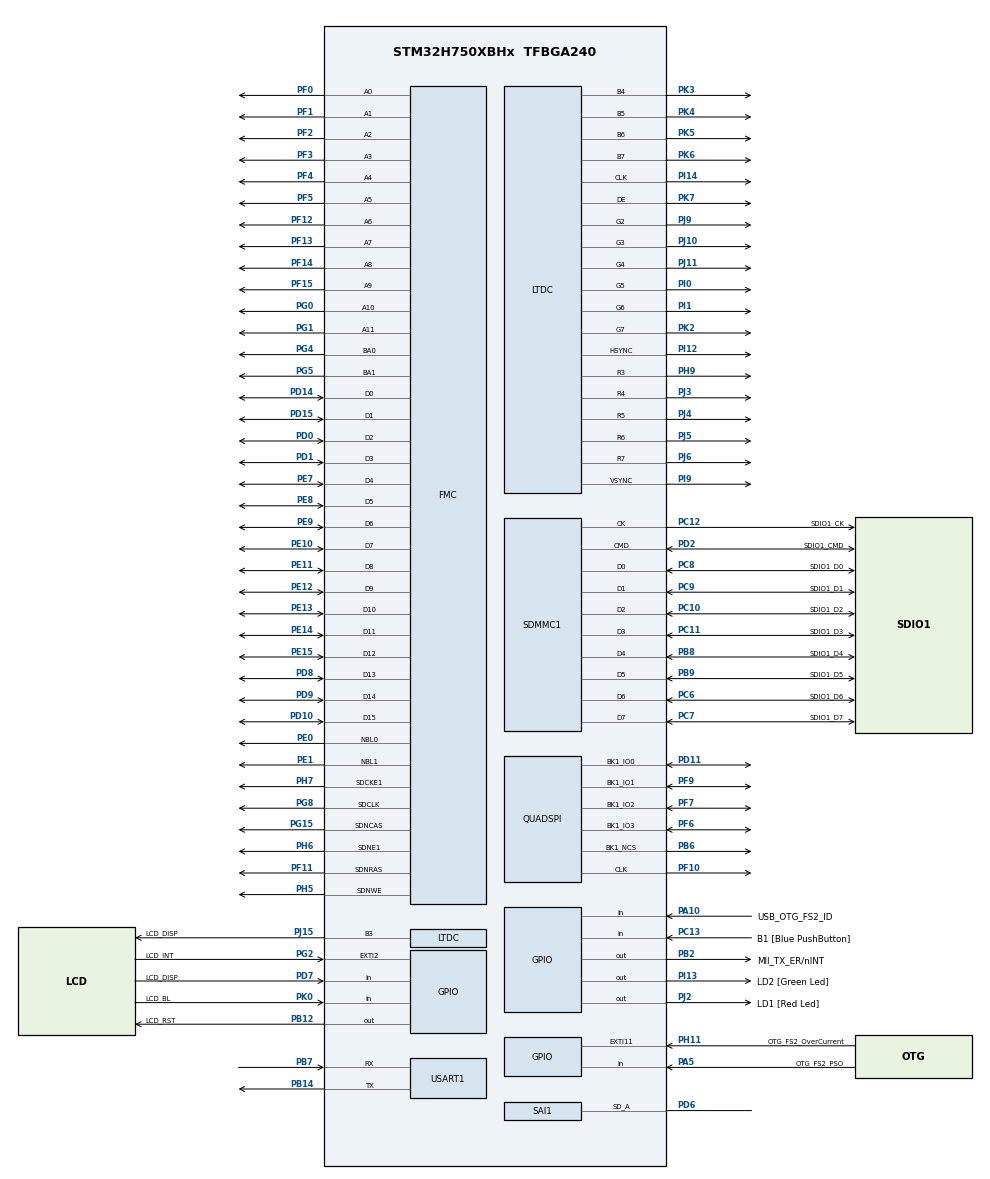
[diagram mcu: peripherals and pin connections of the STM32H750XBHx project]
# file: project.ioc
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FMC.CASLatency1=FMC_SDRAM_CAS_LATENCY_3
FMC.ExitSelfRefreshDelay1=7
FMC.LoadToActiveDelay1=2
FMC.RCDDelay1=2
FMC.RPDelay1=2
FMC.RPDelay2=2
FMC.ReadBurst1=FMC_SDRAM_RBURST_ENABLE
FMC.ReadBurst2=FMC_SDRAM_RBURST_ENABLE
FMC.RowCycleDelay1=7
FMC.RowCycleDelay2=7
FMC.SDClockPeriod1=FMC_SDRAM_CLOCK_PERIOD_2
FMC.SDClockPeriod2=FMC_SDRAM_CLOCK_PERIOD_2
FMC.SelfRefreshTime1=4
FMC.WriteRecoveryTime1=5
FREERTOS.Queues01=controlQueue,16,uint16_t,0,Dynamic,NULL,NULL
FREERTOS.Tasks01=defaultTask,24,128,StartDefaultTask,Default,NULL,Dynamic,NULL,NULL;TouchGFXTask,24,4096,TouchGFX_Task,As external,NULL,Dynamic,NULL,NULL;micListenTask,24,128,micListenTask_handler,Default,NULL,Dynamic,NULL,NULL;consumerTask,24,128,consumerTask_handler,Default,NULL,Dynamic,NULL,NULL;providerTask,24,128,providerTask_handler,Default,NULL,Dynamic,NULL,NULL
FREERTOS.configTOTAL_HEAP_SIZE=75000
FREERTOS.configUSE_NEWLIB_REENTRANT=1
LTDC.ActiveH=272
LTDC.ActiveW=480
LTDC.Alpha_L0=255
LTDC.FBStartAdress_L0=0x90000000
LTDC.ImageHeight_L0=272
LTDC.ImageWidth_L0=480
LTDC.Layers=0
LTDC.VSPolarity=LTDC_VSPOLARITY_AL
LTDC.WindowX1_L0=480
LTDC.WindowY1_L0=272
Mcu.Family=STM32H7
Mcu.Name=STM32H750XBHx
Mcu.Package=TFBGA240
Mdma.MDMA_Channel6.JPEG_OUTFIFO_TH.0.BlockCount=0
Mdma.MDMA_Channel6.JPEG_OUTFIFO_TH.0.BlockDataLength=0
Mdma.MDMA_Channel6.JPEG_OUTFIFO_TH.0.BufferTransferLength=32
Mdma.MDMA_Channel6.JPEG_OUTFIFO_TH.0.CircularMode=MDMA_LINEAR_LIST
Mdma.MDMA_Channel6.JPEG_OUTFIFO_TH.0.DataAlignment=MDMA_DATAALIGN_PACKENABLE
Mdma.MDMA_Channel6.JPEG_OUTFIFO_TH.0.DestBlockAddressOffset=0
Mdma.MDMA_Channel6.JPEG_OUTFIFO_TH.0.DestBurst=MDMA_DEST_BURST_32BEATS
Mdma.MDMA_Channel6.JPEG_OUTFIFO_TH.0.DestDataSize=MDMA_DEST_DATASIZE_BYTE
Mdma.MDMA_Channel6.JPEG_OUTFIFO_TH.0.DestinationInc=MDMA_DEST_INC_BYTE
Mdma.MDMA_Channel6.JPEG_OUTFIFO_TH.0.DstAddress=0
Mdma.MDMA_Channel6.JPEG_OUTFIFO_TH.0.Endianness=MDMA_LITTLE_ENDIANNESS_PRESERVE
Mdma.MDMA_Channel6.JPEG_OUTFIFO_TH.0.Instance=MDMA_Channel6
Mdma.MDMA_Channel6.JPEG_OUTFIFO_TH.0.MaskAddress=0
Mdma.MDMA_Channel6.JPEG_OUTFIFO_TH.0.MaskData=0
Mdma.MDMA_Channel6.JPEG_OUTFIFO_TH.0.Priority=MDMA_PRIORITY_LOW
Mdma.MDMA_Channel6.JPEG_OUTFIFO_TH.0.Rank=First
Mdma.MDMA_Channel6.JPEG_OUTFIFO_TH.0.SourceBlockAddressOffset=0
Mdma.MDMA_Channel6.JPEG_OUTFIFO_TH.0.SourceBurst=MDMA_SOURCE_BURST_SINGLE
Mdma.MDMA_Channel6.JPEG_OUTFIFO_TH.0.SourceDataSize=MDMA_SRC_DATASIZE_WORD
Mdma.MDMA_Channel6.JPEG_OUTFIFO_TH.0.SourceInc=MDMA_SRC_INC_DISABLE
Mdma.MDMA_Channel6.JPEG_OUTFIFO_TH.0.SrcAddress=0
Mdma.MDMA_Channel6.JPEG_OUTFIFO_TH.0.TransferTriggerMode=MDMA_BUFFER_TRANSFER
Mdma.MDMA_Channel6.Request0=JPEG_OUTFIFO_TH
Mdma.MDMA_Channel6.RequestsNb=1
Mdma.MDMA_Channel7.JPEG_INFIFO_TH.0.BlockCount=0
Mdma.MDMA_Channel7.JPEG_INFIFO_TH.0.BlockDataLength=0
Mdma.MDMA_Channel7.JPEG_INFIFO_TH.0.BufferTransferLength=32
Mdma.MDMA_Channel7.JPEG_INFIFO_TH.0.CircularMode=MDMA_LINEAR_LIST
Mdma.MDMA_Channel7.JPEG_INFIFO_TH.0.DataAlignment=MDMA_DATAALIGN_PACKENABLE
Mdma.MDMA_Channel7.JPEG_INFIFO_TH.0.DestBlockAddressOffset=0
Mdma.MDMA_Channel7.JPEG_INFIFO_TH.0.DestBurst=MDMA_DEST_BURST_32BEATS
Mdma.MDMA_Channel7.JPEG_INFIFO_TH.0.DestDataSize=MDMA_DEST_DATASIZE_WORD
Mdma.MDMA_Channel7.JPEG_INFIFO_TH.0.DestinationInc=MDMA_DEST_INC_DISABLE
Mdma.MDMA_Channel7.JPEG_INFIFO_TH.0.DstAddress=0
Mdma.MDMA_Channel7.JPEG_INFIFO_TH.0.Endianness=MDMA_LITTLE_ENDIANNESS_PRESERVE
Mdma.MDMA_Channel7.JPEG_INFIFO_TH.0.Instance=MDMA_Channel7
Mdma.MDMA_Channel7.JPEG_INFIFO_TH.0.MaskAddress=0
Mdma.MDMA_Channel7.JPEG_INFIFO_TH.0.MaskData=0
Mdma.MDMA_Channel7.JPEG_INFIFO_TH.0.Priority=MDMA_PRIORITY_LOW
Mdma.MDMA_Channel7.JPEG_INFIFO_TH.0.Rank=First
Mdma.MDMA_Channel7.JPEG_INFIFO_TH.0.SourceBlockAddressOffset=0
Mdma.MDMA_Channel7.JPEG_INFIFO_TH.0.SourceBurst=MDMA_SOURCE_BURST_32BEATS
Mdma.MDMA_Channel7.JPEG_INFIFO_TH.0.SourceDataSize=MDMA_SRC_DATASIZE_BYTE
Mdma.MDMA_Channel7.JPEG_INFIFO_TH.0.SourceInc=MDMA_SRC_INC_BYTE
Mdma.MDMA_Channel7.JPEG_INFIFO_TH.0.SrcAddress=0
Mdma.MDMA_Channel7.JPEG_INFIFO_TH.0.TransferTriggerMode=MDMA_BUFFER_TRANSFER
Mdma.MDMA_Channel7.Request0=JPEG_INFIFO_TH
Mdma.MDMA_Channel7.RequestsNb=1
Mdma.RequestSet0=MDMA_Channel7
Mdma.RequestSet1=MDMA_Channel6
Mdma.RequestSetsNb=2
NVIC.DMA2D_IRQn=true\:5\:0\:false\:false\:true\:true\:true\:true\:true
NVIC.LTDC_IRQn=true\:5\:0\:false\:false\:true\:true\:true\:true\:true
NVIC.MDMA_IRQn=true\:5\:0\:false\:false\:true\:true\:false\:true\:true
NVIC.PriorityGroup=NVIC_PRIORITYGROUP_4
NVIC.TIM6_DAC_IRQn=true\:15\:0\:false\:false\:true\:false\:false\:true\:true
NVIC.TimeBase=TIM6_DAC_IRQn
NVIC.TimeBaseIP=TIM6
NVIC.USART1_IRQn=true\:5\:0\:false\:false\:true\:true\:true\:true\:true
PA0_C.Signal=ADCx_INP0
PA1.GPIO_Label=MII_RX_CLK
PA1.Signal=ETH_RX_CLK
PA10.GPIO_Label=USB_OTG_FS2_ID
PA10.Signal=GPIO_Input
PA11.GPIO_Label=USB_OTG_FS2_N
PA11.Signal=USB_OTG_FS_DM
PA12.GPIO_Label=USB_OTG_FS2_P
PA12.Signal=USB_OTG_FS_DP
PA13\ (JTMS/SWDIO).Mode=JTAG_4_pins
PA13\ (JTMS/SWDIO).Signal=DEBUG_JTMS-SWDIO
PA14\ (JTCK/SWCLK).Mode=JTAG_4_pins
PA14\ (JTCK/SWCLK).Signal=DEBUG_JTCK-SWCLK
PA15\ (JTDI).Mode=JTAG_4_pins
PA15\ (JTDI).Signal=DEBUG_JTDI
PA1_C.Signal=ADCx_INP1
PA2.GPIO_Label=MII_MDIO
PA2.Signal=ETH_MDIO
PA5.GPIO_Label=OTG_FS2_PSO
PA5.Signal=GPIO_Input
PA6.Signal=S_TIM13_CH1
PA7.GPIO_Label=MII_RX_DV
PA7.Signal=ETH_RX_DV
PA8.Signal=S_TIM1_CH1
PA9.GPIO_Label=VBUS_FS2
PA9.Signal=USB_OTG_FS_VBUS
PB0.GPIO_Label=MII_RX_D2
PB0.Signal=ETH_RXD2
PB1.GPIO_Label=MII_RX_D3
PB1.Signal=ETH_RXD3
PB10.GPIO_Label=VCP_TX
PB10.Signal=USART3_TX
PB11.GPIO_Label=VCP_RX
PB11.Signal=USART3_RX
PB12.GPIO_Label=LCD_RST
PB12.Signal=GPIO_Output
PB13.GPIO_Label=FDCAN2_TX
PB13.Signal=FDCAN2_TX
PB14.Mode=Asynchronous
PB14.Signal=USART1_TX
PB15.Signal=SPI2_MOSI
PB2.GPIO_Label=MII_TX_ER/nINT
PB2.Signal=GPIO_Output
PB3\ (JTDO/TRACESWO).Mode=JTAG_4_pins
PB3\ (JTDO/TRACESWO).Signal=DEBUG_JTDO-SWO
PB4\ (NJTRST).Signal=SPI2_NSS
PB5.GPIO_Label=FDCAN2_RX
PB5.Signal=FDCAN2_RX
PB6.GPIO_Speed=GPIO_SPEED_FREQ_VERY_HIGH
PB6.Mode=Single Bank 1
PB6.Signal=QUADSPI_BK1_NCS
PB7.Mode=Asynchronous
PB7.Signal=USART1_RX
PB8.GPIO_Label=SDIO1_D4
PB8.Mode=mmc_8_bits_Wide_bus
PB8.Signal=SDMMC1_D4
PB9.GPIO_Label=SDIO1_D5
PB9.Mode=mmc_8_bits_Wide_bus
PB9.Signal=SDMMC1_D5
PC0.Signal=ADCx_INP10
PC1.GPIO_Label=MII_MDC
PC1.Signal=ETH_MDC
PC10.GPIO_Label=SDIO1_D2
PC10.Mode=mmc_8_bits_Wide_bus
PC10.Signal=SDMMC1_D2
PC11.GPIO_Label=SDIO1_D3
PC11.Mode=mmc_8_bits_Wide_bus
PC11.Signal=SDMMC1_D3
PC12.GPIO_Label=SDIO1_CK
PC12.Mode=mmc_8_bits_Wide_bus
PC12.Signal=SDMMC1_CK
PC13.GPIO_Label=B1 [Blue PushButton]
PC13.Signal=GPIO_Input
PC14-OSC32_IN\ (OSC32_IN).GPIO_Label=OSC32_IN
PC14-OSC32_IN\ (OSC32_IN).Mode=LSE-External-Clock-Source
PC14-OSC32_IN\ (OSC32_IN).Signal=RCC_OSC32_IN
PC15-OSC32_OUT\ (OSC32_OUT).GPIO_Label=OSC32_OUT
PC15-OSC32_OUT\ (OSC32_OUT).Signal=RCC_OSC32_OUT
PC2.GPIO_Label=MII_TXD2
PC2.Signal=ETH_TXD2
PC2_C.Signal=SharedAnalog_PC2
PC3.GPIO_Label=MII_TX_CLK
PC3.Signal=ETH_TX_CLK
PC3_C.Signal=ADC3_INP1
PC4.GPIO_Label=MII_RXD0
PC4.Signal=ETH_RXD0
PC5.GPIO_Label=MII_RXD1
PC5.Signal=ETH_RXD1
PC6.GPIO_Label=SDIO1_D6
PC6.Mode=mmc_8_bits_Wide_bus
PC6.Signal=SDMMC1_D6
PC7.GPIO_Label=SDIO1_D7
PC7.Mode=mmc_8_bits_Wide_bus
PC7.Signal=SDMMC1_D7
PC8.GPIO_Label=SDIO1_D0
PC8.Mode=mmc_8_bits_Wide_bus
PC8.Signal=SDMMC1_D0
PC9.GPIO_Label=SDIO1_D1
PC9.Mode=mmc_8_bits_Wide_bus
PC9.Signal=SDMMC1_D1
PD0.Signal=FMC_D2_DA2
PD1.Signal=FMC_D3_DA3
PD10.Signal=FMC_D15_DA15
PD11.GPIO_Speed=GPIO_SPEED_FREQ_VERY_HIGH
PD11.Mode=Single Bank 1
PD11.Signal=QUADSPI_BK1_IO0
PD14.Signal=FMC_D0_DA0
PD15.Signal=FMC_D1_DA1
PD2.GPIO_Label=SDIO1_CMD
PD2.Mode=mmc_8_bits_Wide_bus
PD2.Signal=SDMMC1_CMD
PD3.Signal=SPI2_SCK
PD6.Mode=SAI_A_SPDIF
PD6.Signal=SAI1_SD_A
PD7.GPIO_Label=LCD_DISP
PD7.Signal=GPIO_Input
PD8.Signal=FMC_D13_DA13
PD9.Signal=FMC_D14_DA14
PE0.Signal=FMC_NBL0
PE1.Signal=FMC_NBL1
PE10.Signal=FMC_D7_DA7
PE11.Signal=FMC_D8_DA8
PE12.Signal=FMC_D9_DA9
PE13.Signal=FMC_D10_DA10
PE14.Signal=FMC_D11_DA11
PE15.Signal=FMC_D12_DA12
PE2.GPIO_Label=MII_TXD3
PE2.Signal=ETH_TXD3
PE4.Signal=SAI4_D2
PE5.Signal=SAI4_CK2
PE7.Signal=FMC_D4_DA4
PE8.Signal=FMC_D5_DA5
PE9.Signal=FMC_D6_DA6
PF0.Signal=FMC_A0
PF1.Signal=FMC_A1
PF10.Mode=Single Bank 1
PF10.Signal=QUADSPI_CLK
PF11.Signal=FMC_SDNRAS
PF12.Signal=FMC_A6
PF13.Signal=FMC_A7
PF14.Signal=FMC_A8
PF15.Signal=FMC_A9
PF2.Signal=FMC_A2
PF3.Signal=FMC_A3
PF4.Signal=FMC_A4
PF5.Signal=FMC_A5
PF6.GPIO_Speed=GPIO_SPEED_FREQ_VERY_HIGH
PF6.Mode=Single Bank 1
PF6.Signal=QUADSPI_BK1_IO3
PF7.GPIO_Speed=GPIO_SPEED_FREQ_VERY_HIGH
PF7.Mode=Single Bank 1
PF7.Signal=QUADSPI_BK1_IO2
PF8.Signal=ADC3_INP7
PF9.GPIO_Speed=GPIO_SPEED_FREQ_VERY_HIGH
PF9.Mode=Single Bank 1
PF9.Signal=QUADSPI_BK1_IO1
PG0.Signal=FMC_A10
PG1.Signal=FMC_A11
PG10.Signal=SAI2_SD_B
PG11.GPIO_Label=MII_TX_EN
PG11.Signal=ETH_TX_EN
PG12.GPIO_Label=MII_TXD1
PG12.Signal=ETH_TXD1
PG13.GPIO_Label=MII_TXD0
PG13.Signal=ETH_TXD0
PG15.Signal=FMC_SDNCAS
PG2.GPIO_Label=LCD_INT
PG2.Signal=GPXTI2
PG4.Signal=FMC_A14_BA0
PG5.Signal=FMC_A15_BA1
PG7.GPIO_Label=audio_Int
PG7.Signal=SAI1_MCLK_A
PG8.Signal=FMC_SDCLK
PH0-OSC_IN\ (PH0).GPIO_Label=OSC_IN
PH0-OSC_IN\ (PH0).Mode=HSE-External-Clock-Source
PH0-OSC_IN\ (PH0).Signal=RCC_OSC_IN
PH1-OSC_OUT\ (PH1).GPIO_Label=OSC_OUT
PH1-OSC_OUT\ (PH1).Signal=RCC_OSC_OUT
PH11.GPIO_Label=OTG_FS2_OverCurrent
PH11.Signal=GPXTI11
PH13.GPIO_Label=FDCAN1_TX
PH13.Signal=FDCAN1_TX
PH14.GPIO_Label=FDCAN1_RX
PH14.Signal=FDCAN1_RX
PH15.Signal=TIM8_CH3N
PH2.GPIO_Label=MII_CRS
PH2.Signal=ETH_CRS
PH3.GPIO_Label=MII_COL
PH3.Signal=ETH_COL
PH5.Signal=FMC_SDNWE
PH6.Mode=SdramChipSelect2_1
PH6.Signal=FMC_SDNE1
PH7.Mode=SdramChipSelect2_1
PH7.Signal=FMC_SDCKE1
PH9.Mode=RGB565
PH9.Signal=LTDC_R3
PI0.Mode=RGB565
PI0.Signal=LTDC_G5
PI1.Mode=RGB565
PI1.Signal=LTDC_G6
PI10.GPIO_Label=MII_RX_ER
PI10.Signal=ETH_RX_ER
PI12.Mode=RGB565
PI12.Signal=LTDC_HSYNC
PI13.GPIO_Label=LD2 [Green Led]
PI13.Signal=GPIO_Output
PI14.Mode=RGB565
PI14.Signal=LTDC_CLK
PI15.Signal=LTDC_R0
PI2.Signal=SPI2_MISO
PI4.Signal=SAI2_MCLK_A
PI5.Signal=SAI2_SCK_A
PI6.Signal=SAI2_SD_A
PI7.Signal=SAI2_FS_A
PI9.Mode=RGB565
PI9.Signal=LTDC_VSYNC
PJ0.Signal=LTDC_R1
PJ1.Signal=LTDC_R2
PJ10.Mode=RGB565
PJ10.Signal=LTDC_G3
PJ11.Mode=RGB565
PJ11.Signal=LTDC_G4
PJ12.Signal=LTDC_B0
PJ13.Signal=LTDC_B1
PJ14.Signal=LTDC_B2
PJ15.GPIO_Label=LCD_DISP
PJ15.Mode=RGB565
PJ15.Signal=LTDC_B3
PJ2.GPIO_Label=LD1 [Red Led]
PJ2.Signal=GPIO_Output
PJ3.Mode=RGB565
PJ3.Signal=LTDC_R4
PJ4.Mode=RGB565
PJ4.Signal=LTDC_R5
PJ5.Mode=RGB565
PJ5.Signal=LTDC_R6
PJ6.Mode=RGB565
PJ6.Signal=LTDC_R7
PJ7.Signal=LTDC_G0
PJ8.Signal=LTDC_G1
PJ9.Mode=RGB565
PJ9.Signal=LTDC_G2
PK0.GPIO_Label=LCD_BL
PK0.Signal=GPIO_Input
PK2.Mode=RGB565
PK2.Signal=LTDC_G7
PK3.Mode=RGB565
PK3.Signal=LTDC_B4
PK4.Mode=RGB565
PK4.Signal=LTDC_B5
PK5.Mode=RGB565
PK5.Signal=LTDC_B6
PK6.Mode=RGB565
PK6.Signal=LTDC_B7
PK7.Mode=RGB565
PK7.Signal=LTDC_DE
ProjectManager.HeapSize=0x200
ProjectManager.StackSize=0x400
ProjectManager.TargetToolchain=STM32CubeIDE
QUADSPI.ChipSelectHighTime=QSPI_CS_HIGH_TIME_3_CYCLE
QUADSPI.ClockPrescaler=3
QUADSPI.FlashSize=26
QUADSPI.SampleShifting=QSPI_SAMPLE_SHIFTING_HALFCYCLE
RCC.ADCFreq_Value=30000000
RCC.APB1Freq_Value=64000000
RCC.APB2Freq_Value=64000000
RCC.APB3Freq_Value=64000000
RCC.APB4Freq_Value=64000000
RCC.CortexFreq_Value=64000000
RCC.DIVM1=22
RCC.DIVM2=2
RCC.DIVN1=169
RCC.DIVN2=12
RCC.DIVN3=192
RCC.DIVP2=5
RCC.DIVQ1=4
RCC.HCLKFreq_Value=64000000
RCC.PLL2FRACN=0
RCC.PLL3FRACN=0
RCC.PLLFRACN=0
RCC.PLLSourceVirtual=RCC_PLLSOURCE_HSE
RCC.PWR_Regulator_Voltage_Scale=PWR_REGULATOR_VOLTAGE_SCALE2
RCC.SYSCLKFreq_VALUE=64000000
RCC.USBFreq_Value=48011363.63636364
SAI1.Instance-SAI_A_SPDIF=SAI$Index_Block_A
SAI1.RealAudioFreq-SAI_A_SPDIF=750.177 KHz
SAI1.VirtualMode-SAI_A_SPDIF=VM_SPDIF
SH.ADCx_INP0.0=ADC2_INP0
SH.ADCx_INP0.1=ADC1_INP0
SH.ADCx_INP1.0=ADC2_INP1
SH.ADCx_INP1.1=ADC1_INP1
SH.ADCx_INP10.0=ADC1_INP10
SH.ADCx_INP10.1=ADC3_INP10
SH.FMC_A0.0=FMC_A0,12b-sda1
SH.FMC_A1.0=FMC_A1,12b-sda1
SH.FMC_A10.0=FMC_A10,12b-sda1
SH.FMC_A11.0=FMC_A11,12b-sda1
SH.FMC_A14_BA0.0=FMC_BA0,FourSdramBanks1
SH.FMC_A15_BA1.0=FMC_BA1,FourSdramBanks1
SH.FMC_A2.0=FMC_A2,12b-sda1
SH.FMC_A3.0=FMC_A3,12b-sda1
SH.FMC_A4.0=FMC_A4,12b-sda1
SH.FMC_A5.0=FMC_A5,12b-sda1
SH.FMC_A6.0=FMC_A6,12b-sda1
SH.FMC_A7.0=FMC_A7,12b-sda1
SH.FMC_A8.0=FMC_A8,12b-sda1
SH.FMC_A9.0=FMC_A9,12b-sda1
SH.FMC_D0_DA0.0=FMC_D0,sd-16b-d1
SH.FMC_D10_DA10.0=FMC_D10,sd-16b-d1
SH.FMC_D11_DA11.0=FMC_D11,sd-16b-d1
SH.FMC_D12_DA12.0=FMC_D12,sd-16b-d1
SH.FMC_D13_DA13.0=FMC_D13,sd-16b-d1
SH.FMC_D14_DA14.0=FMC_D14,sd-16b-d1
SH.FMC_D15_DA15.0=FMC_D15,sd-16b-d1
SH.FMC_D1_DA1.0=FMC_D1,sd-16b-d1
SH.FMC_D2_DA2.0=FMC_D2,sd-16b-d1
SH.FMC_D3_DA3.0=FMC_D3,sd-16b-d1
SH.FMC_D4_DA4.0=FMC_D4,sd-16b-d1
SH.FMC_D5_DA5.0=FMC_D5,sd-16b-d1
SH.FMC_D6_DA6.0=FMC_D6,sd-16b-d1
SH.FMC_D7_DA7.0=FMC_D7,sd-16b-d1
SH.FMC_D8_DA8.0=FMC_D8,sd-16b-d1
SH.FMC_D9_DA9.0=FMC_D9,sd-16b-d1
SH.FMC_NBL0.0=FMC_NBL0,Sd2ByteEnable1
SH.FMC_NBL1.0=FMC_NBL1,Sd2ByteEnable1
SH.FMC_SDCLK.0=FMC_SDCLK,12b-sda1
SH.FMC_SDNCAS.0=FMC_SDNCAS,12b-sda1
SH.FMC_SDNRAS.0=FMC_SDNRAS,12b-sda1
SH.FMC_SDNWE.0=FMC_SDNWE,12b-sda1
SH.S_TIM13_CH1.0=TIM13_CH1
SH.S_TIM1_CH1.0=TIM1_CH1
SH.SharedAnalog_PC2.0=ADC3_INP0
SH.SharedAnalog_PC2.1=ADC3_INN1
STMicroelectronics.X-CUBE-TOUCHGFX.4.23.0.ApplicationCcGraphicsJjApplication=TouchGFXOoGenerator
STMicroelectronics.X-CUBE-TOUCHGFX.4.23.0.tgfx_buffering_strategy=Double
STMicroelectronics.X-CUBE-TOUCHGFX.4.23.0.tgfx_display_interface=disp_ltdc
STMicroelectronics.X-CUBE-TOUCHGFX.4.23.0.tgfx_hardware_accelerator=dma_2d
STMicroelectronics.X-CUBE-TOUCHGFX.4.23.0.tgfx_vsync=vsync_ltdc
STMicroelectronics.X-CUBE-TOUCHGFX.4.23.0_IsPackSelfContextualization=true
USART1.VirtualMode-Asynchronous=VM_ASYNC
VP_CRC_VS_CRC.Mode=CRC_Activate
VP_DMA2D_VS_DMA2D.Mode=DMA2D_Activate
VP_FREERTOS_VS_CMSIS_V2.Mode=CMSIS_V2
VP_JPEG_VS_JPEG.Mode=JPEG_Activate
VP_LIBJPEG_VS_JPEGLIB.Mode=Enabled
VP_STMicroelectronics.X-CUBE-TOUCHGFX_VS_GraphicsJjApplication_4.23.0.Mode=GraphicsJjApplication
VP_SYS_VS_tim6.Mode=TIM6
board=STM32H750B-DK

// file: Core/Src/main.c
/* USER CODE BEGIN Header */
/**
  ******************************************************************************
  * @file           : main.c
  * @brief          : Main program body
  ******************************************************************************
  * @attention
  *
  * Copyright (c) 2024 STMicroelectronics.
  * All rights reserved.
  *
  * This software is licensed under terms that can be found in the LICENSE file
  * in the root directory of this software component.
  * If no LICENSE file comes with this software, it is provided AS-IS.
  *
  ******************************************************************************
  */
/* USER CODE END Header */
#include "main.h"
#include "cmsis_os.h"
#include "libjpeg.h"
#include "app_touchgfx.h"

/* USER CODE BEGIN Includes */
#include "stm32h750b_discovery_qspi.h"
#include "stm32h750b_discovery_sdram.h"
#include "pv_st_h750b.h"
#include "queue.h"

/* USER CODE END Includes */

/* USER CODE BEGIN PM */
pv_picovoice_t *pvhandle = NULL;
/* USER CODE END PM */

CRC_HandleTypeDef hcrc;

DMA2D_HandleTypeDef hdma2d;

JPEG_HandleTypeDef hjpeg;
MDMA_HandleTypeDef hmdma_jpeg_infifo_th;
MDMA_HandleTypeDef hmdma_jpeg_outfifo_th;

LTDC_HandleTypeDef hltdc;

QSPI_HandleTypeDef hqspi;

SAI_HandleTypeDef hsai_BlockA1;

MMC_HandleTypeDef hmmc1;

UART_HandleTypeDef huart1;

SDRAM_HandleTypeDef hsdram1;

/* Definitions for defaultTask */
osThreadId_t defaultTaskHandle;
const osThreadAttr_t defaultTask_attributes = {
  .name = "defaultTask",
  .stack_size = 128 * 4,
  .priority = (osPriority_t) osPriorityNormal,
};
/* Definitions for TouchGFXTask */
osThreadId_t TouchGFXTaskHandle;
const osThreadAttr_t TouchGFXTask_attributes = {
  .name = "TouchGFXTask",
  .stack_size = 4096 * 4,
  .priority = (osPriority_t) osPriorityNormal,
};
/* Definitions for micListenTask */
osThreadId_t micListenTaskHandle;
const osThreadAttr_t micListenTask_attributes = {
  .name = "micListenTask",
  .stack_size = 128 * 4,
  .priority = (osPriority_t) osPriorityNormal,
};
/* Definitions for consumerTask */
osThreadId_t consumerTaskHandle;
const osThreadAttr_t consumerTask_attributes = {
  .name = "consumerTask",
  .stack_size = 128 * 4,
  .priority = (osPriority_t) osPriorityNormal,
};
/* Definitions for providerTask */
osThreadId_t providerTaskHandle;
const osThreadAttr_t providerTask_attributes = {
  .name = "providerTask",
  .stack_size = 128 * 4,
  .priority = (osPriority_t) osPriorityNormal,
};
/* Definitions for controlQueue */
osMessageQueueId_t controlQueueHandle;
const osMessageQueueAttr_t controlQueue_attributes = {
  .name = "controlQueue"
};

void SystemClock_Config(void);
static void MX_GPIO_Init(void);
static void MX_MDMA_Init(void);
static void MX_DMA2D_Init(void);
static void MX_FMC_Init(void);
static void MX_SAI1_Init(void);
static void MX_QUADSPI_Init(void);
static void MX_USART1_UART_Init(void);
static void MX_LTDC_Init(void);
static void MX_SDMMC1_MMC_Init(void);
static void MX_JPEG_Init(void);
static void MX_CRC_Init(void);
void StartDefaultTask(void *argument);
extern void TouchGFX_Task(void *argument);
void micListenTask_handler(void *argument);
void consumerTask_handler(void *argument);
void providerTask_handler(void *argument);

int main(void)
{
  /* USER CODE BEGIN 1 */
  SCB_EnableICache();
  SCB_EnableDCache();
  /* USER CODE END 1 */

  /* MCU Configuration--------------------------------------------------------*/

  /* Reset of all peripherals, Initializes the Flash interface and the Systick. */
  HAL_Init();

  /* Configure the system clock */
  SystemClock_Config();

  /* Initialize all configured peripherals */
  MX_GPIO_Init();
  MX_MDMA_Init();
  MX_DMA2D_Init();
  MX_FMC_Init();
  MX_SAI1_Init();
  MX_QUADSPI_Init();
  MX_USART1_UART_Init();
  MX_LTDC_Init();
  MX_SDMMC1_MMC_Init();
  MX_JPEG_Init();
  MX_LIBJPEG_Init();
  MX_CRC_Init();
  MX_TouchGFX_Init();
  /* Call PreOsInit function */
  MX_TouchGFX_PreOSInit();

  /* Init scheduler */
  osKernelInitialize();

  /* Create the queue(s) */
  /* creation of controlQueue */
  controlQueueHandle = osMessageQueueNew (16, sizeof(uint16_t), &controlQueue_attributes);

  /* Create the thread(s) */
  /* creation of defaultTask */
  defaultTaskHandle = osThreadNew(StartDefaultTask, NULL, &defaultTask_attributes);

  /* creation of TouchGFXTask */
  TouchGFXTaskHandle = osThreadNew(TouchGFX_Task, NULL, &TouchGFXTask_attributes);

  /* creation of micListenTask */
  micListenTaskHandle = osThreadNew(micListenTask_handler, NULL, &micListenTask_attributes);

  /* creation of consumerTask */
  consumerTaskHandle = osThreadNew(consumerTask_handler, NULL, &consumerTask_attributes);

  /* creation of providerTask */
  providerTaskHandle = osThreadNew(providerTask_handler, NULL, &providerTask_attributes);

  /* Start scheduler */
  osKernelStart();

  /* We should never get here as control is now taken by the scheduler */
  /* Infinite loop */
  while (1)
  {

    /* USER CODE BEGIN 3 */
  }
  pv_deinit(pvhandle);
  /* USER CODE END 3 */
}

void SystemClock_Config(void)
{
  RCC_OscInitTypeDef RCC_OscInitStruct = {0};
  RCC_ClkInitTypeDef RCC_ClkInitStruct = {0};

  /** Supply configuration update enable
  */
  HAL_PWREx_ConfigSupply(PWR_LDO_SUPPLY);

  /** Configure the main internal regulator output voltage
  */
  __HAL_PWR_VOLTAGESCALING_CONFIG(PWR_REGULATOR_VOLTAGE_SCALE2);

  while(!__HAL_PWR_GET_FLAG(PWR_FLAG_VOSRDY)) {}

  /** Initializes the RCC Oscillators according to the specified parameters
  * in the RCC_OscInitTypeDef structure.
  */
  RCC_OscInitStruct.OscillatorType = RCC_OSCILLATORTYPE_HSI|RCC_OSCILLATORTYPE_HSE;
  RCC_OscInitStruct.HSEState = RCC_HSE_BYPASS;
  RCC_OscInitStruct.HSIState = RCC_HSI_DIV1;
  RCC_OscInitStruct.HSICalibrationValue = RCC_HSICALIBRATION_DEFAULT;
  RCC_OscInitStruct.PLL.PLLState = RCC_PLL_ON;
  RCC_OscInitStruct.PLL.PLLSource = RCC_PLLSOURCE_HSE;
  RCC_OscInitStruct.PLL.PLLM = 22;
  RCC_OscInitStruct.PLL.PLLN = 169;
  RCC_OscInitStruct.PLL.PLLP = 2;
  RCC_OscInitStruct.PLL.PLLQ = 4;
  RCC_OscInitStruct.PLL.PLLR = 2;
  RCC_OscInitStruct.PLL.PLLRGE = RCC_PLL1VCIRANGE_0;
  RCC_OscInitStruct.PLL.PLLVCOSEL = RCC_PLL1VCOWIDE;
  RCC_OscInitStruct.PLL.PLLFRACN = 0;
  if (HAL_RCC_OscConfig(&RCC_OscInitStruct) != HAL_OK)
  {
    Error_Handler();
  }

  /** Initializes the CPU, AHB and APB buses clocks
  */
  RCC_ClkInitStruct.ClockType = RCC_CLOCKTYPE_HCLK|RCC_CLOCKTYPE_SYSCLK
                              |RCC_CLOCKTYPE_PCLK1|RCC_CLOCKTYPE_PCLK2
                              |RCC_CLOCKTYPE_D3PCLK1|RCC_CLOCKTYPE_D1PCLK1;
  RCC_ClkInitStruct.SYSCLKSource = RCC_SYSCLKSOURCE_HSI;
  RCC_ClkInitStruct.SYSCLKDivider = RCC_SYSCLK_DIV1;
  RCC_ClkInitStruct.AHBCLKDivider = RCC_HCLK_DIV1;
  RCC_ClkInitStruct.APB3CLKDivider = RCC_APB3_DIV1;
  RCC_ClkInitStruct.APB1CLKDivider = RCC_APB1_DIV1;
  RCC_ClkInitStruct.APB2CLKDivider = RCC_APB2_DIV1;
  RCC_ClkInitStruct.APB4CLKDivider = RCC_APB4_DIV1;

  if (HAL_RCC_ClockConfig(&RCC_ClkInitStruct, FLASH_LATENCY_1) != HAL_OK)
  {
    Error_Handler();
  }
}

static void MX_CRC_Init(void)
{

  hcrc.Instance = CRC;
  hcrc.Init.DefaultPolynomialUse = DEFAULT_POLYNOMIAL_ENABLE;
  hcrc.Init.DefaultInitValueUse = DEFAULT_INIT_VALUE_ENABLE;
  hcrc.Init.InputDataInversionMode = CRC_INPUTDATA_INVERSION_NONE;
  hcrc.Init.OutputDataInversionMode = CRC_OUTPUTDATA_INVERSION_DISABLE;
  hcrc.InputDataFormat = CRC_INPUTDATA_FORMAT_BYTES;
  if (HAL_CRC_Init(&hcrc) != HAL_OK)
  {
    Error_Handler();
  }

}

static void MX_DMA2D_Init(void)
{

  hdma2d.Instance = DMA2D;
  hdma2d.Init.Mode = DMA2D_M2M;
  hdma2d.Init.ColorMode = DMA2D_OUTPUT_ARGB8888;
  hdma2d.Init.OutputOffset = 0;
  hdma2d.LayerCfg[1].InputOffset = 0;
  hdma2d.LayerCfg[1].InputColorMode = DMA2D_INPUT_ARGB8888;
  hdma2d.LayerCfg[1].AlphaMode = DMA2D_NO_MODIF_ALPHA;
  hdma2d.LayerCfg[1].InputAlpha = 0;
  hdma2d.LayerCfg[1].AlphaInverted = DMA2D_REGULAR_ALPHA;
  hdma2d.LayerCfg[1].RedBlueSwap = DMA2D_RB_REGULAR;
  hdma2d.LayerCfg[1].ChromaSubSampling = DMA2D_NO_CSS;
  if (HAL_DMA2D_Init(&hdma2d) != HAL_OK)
  {
    Error_Handler();
  }
  if (HAL_DMA2D_ConfigLayer(&hdma2d, 1) != HAL_OK)
  {
    Error_Handler();
  }

}

static void MX_JPEG_Init(void)
{

  hjpeg.Instance = JPEG;
  if (HAL_JPEG_Init(&hjpeg) != HAL_OK)
  {
    Error_Handler();
  }

}

static void MX_LTDC_Init(void)
{

  LTDC_LayerCfgTypeDef pLayerCfg = {0};

  hltdc.Instance = LTDC;
  hltdc.Init.HSPolarity = LTDC_HSPOLARITY_AL;
  hltdc.Init.VSPolarity = LTDC_VSPOLARITY_AL;
  hltdc.Init.DEPolarity = LTDC_DEPOLARITY_AL;
  hltdc.Init.PCPolarity = LTDC_PCPOLARITY_IPC;
  hltdc.Init.HorizontalSync = 7;
  hltdc.Init.VerticalSync = 3;
  hltdc.Init.AccumulatedHBP = 14;
  hltdc.Init.AccumulatedVBP = 5;
  hltdc.Init.AccumulatedActiveW = 494;
  hltdc.Init.AccumulatedActiveH = 277;
  hltdc.Init.TotalWidth = 500;
  hltdc.Init.TotalHeigh = 279;
  hltdc.Init.Backcolor.Blue = 0;
  hltdc.Init.Backcolor.Green = 0;
  hltdc.Init.Backcolor.Red = 0;
  if (HAL_LTDC_Init(&hltdc) != HAL_OK)
  {
    Error_Handler();
  }
  pLayerCfg.WindowX0 = 0;
  pLayerCfg.WindowX1 = 480;
  pLayerCfg.WindowY0 = 0;
  pLayerCfg.WindowY1 = 272;
  pLayerCfg.PixelFormat = LTDC_PIXEL_FORMAT_ARGB8888;
  pLayerCfg.Alpha = 255;
  pLayerCfg.Alpha0 = 0;
  pLayerCfg.BlendingFactor1 = LTDC_BLENDING_FACTOR1_CA;
  pLayerCfg.BlendingFactor2 = LTDC_BLENDING_FACTOR2_CA;
  pLayerCfg.FBStartAdress = 0x90000000;
  pLayerCfg.ImageWidth = 480;
  pLayerCfg.ImageHeight = 272;
  pLayerCfg.Backcolor.Blue = 0;
  pLayerCfg.Backcolor.Green = 0;
  pLayerCfg.Backcolor.Red = 0;
  if (HAL_LTDC_ConfigLayer(&hltdc, &pLayerCfg, 0) != HAL_OK)
  {
    Error_Handler();
  }

}

static void MX_QUADSPI_Init(void)
{

  /* USER CODE BEGIN QUADSPI_Init 0 */
  BSP_QSPI_Init_t qspi_initParams;
  /* USER CODE END QUADSPI_Init 0 */

  /* QUADSPI parameter configuration*/
  hqspi.Instance = QUADSPI;
  hqspi.Init.ClockPrescaler = 3;
  hqspi.Init.FifoThreshold = 1;
  hqspi.Init.SampleShifting = QSPI_SAMPLE_SHIFTING_HALFCYCLE;
  hqspi.Init.FlashSize = 26;
  hqspi.Init.ChipSelectHighTime = QSPI_CS_HIGH_TIME_3_CYCLE;
  hqspi.Init.ClockMode = QSPI_CLOCK_MODE_0;
  hqspi.Init.FlashID = QSPI_FLASH_ID_1;
  hqspi.Init.DualFlash = QSPI_DUALFLASH_DISABLE;
  if (HAL_QSPI_Init(&hqspi) != HAL_OK)
  {
    Error_Handler();
  }
  /* USER CODE BEGIN QUADSPI_Init 2 */
  qspi_initParams.InterfaceMode = MT25TL01G_QPI_MODE;
  qspi_initParams.TransferRate  = MT25TL01G_DTR_TRANSFER ;
  qspi_initParams.DualFlashMode = MT25TL01G_DUALFLASH_ENABLE;
  BSP_QSPI_DeInit(0);
  if (BSP_QSPI_Init(0, &qspi_initParams) != BSP_ERROR_NONE)
  {
    Error_Handler( );
  }
  if(BSP_QSPI_EnableMemoryMappedMode(0) != BSP_ERROR_NONE)
  {
    Error_Handler( );
  }
  /* USER CODE END QUADSPI_Init 2 */

}

static void MX_SAI1_Init(void)
{

  hsai_BlockA1.Instance = SAI1_Block_A;
  hsai_BlockA1.Init.Protocol = SAI_SPDIF_PROTOCOL;
  hsai_BlockA1.Init.AudioMode = SAI_MODEMASTER_TX;
  hsai_BlockA1.Init.Synchro = SAI_ASYNCHRONOUS;
  hsai_BlockA1.Init.OutputDrive = SAI_OUTPUTDRIVE_DISABLE;
  hsai_BlockA1.Init.FIFOThreshold = SAI_FIFOTHRESHOLD_EMPTY;
  hsai_BlockA1.Init.AudioFrequency = SAI_AUDIO_FREQUENCY_48K;
  hsai_BlockA1.Init.MonoStereoMode = SAI_STEREOMODE;
  hsai_BlockA1.Init.CompandingMode = SAI_NOCOMPANDING;
  hsai_BlockA1.Init.PdmInit.Activation = DISABLE;
  hsai_BlockA1.Init.PdmInit.MicPairsNbr = 1;
  hsai_BlockA1.Init.PdmInit.ClockEnable = SAI_PDM_CLOCK1_ENABLE;
  if (HAL_SAI_Init(&hsai_BlockA1) != HAL_OK)
  {
    Error_Handler();
  }
  /* USER CODE BEGIN SAI1_Init 2 */

  pv_deinit(pvhandle);
  if (pv_init(pvhandle) != PV_STATUS_SUCCESS) {
	Error_Handler();
  }

  /* USER CODE END SAI1_Init 2 */

}

static void MX_SDMMC1_MMC_Init(void)
{

  hmmc1.Instance = SDMMC1;
  hmmc1.Init.ClockEdge = SDMMC_CLOCK_EDGE_RISING;
  hmmc1.Init.ClockPowerSave = SDMMC_CLOCK_POWER_SAVE_DISABLE;
  hmmc1.Init.BusWide = SDMMC_BUS_WIDE_8B;
  hmmc1.Init.HardwareFlowControl = SDMMC_HARDWARE_FLOW_CONTROL_DISABLE;
  hmmc1.Init.ClockDiv = 0;
  if (HAL_MMC_Init(&hmmc1) != HAL_OK)
  {
    Error_Handler();
  }

}

static void MX_USART1_UART_Init(void)
{

  huart1.Instance = USART1;
  huart1.Init.BaudRate = 115200;
  huart1.Init.WordLength = UART_WORDLENGTH_8B;
  huart1.Init.StopBits = UART_STOPBITS_1;
  huart1.Init.Parity = UART_PARITY_NONE;
  huart1.Init.Mode = UART_MODE_TX_RX;
  huart1.Init.HwFlowCtl = UART_HWCONTROL_NONE;
  huart1.Init.OverSampling = UART_OVERSAMPLING_16;
  huart1.Init.OneBitSampling = UART_ONE_BIT_SAMPLE_DISABLE;
  huart1.Init.ClockPrescaler = UART_PRESCALER_DIV1;
  huart1.AdvancedInit.AdvFeatureInit = UART_ADVFEATURE_NO_INIT;
  if (HAL_UART_Init(&huart1) != HAL_OK)
  {
    Error_Handler();
  }
  if (HAL_UARTEx_SetTxFifoThreshold(&huart1, UART_TXFIFO_THRESHOLD_1_8) != HAL_OK)
  {
    Error_Handler();
  }
  if (HAL_UARTEx_SetRxFifoThreshold(&huart1, UART_RXFIFO_THRESHOLD_1_8) != HAL_OK)
  {
    Error_Handler();
  }
  if (HAL_UARTEx_DisableFifoMode(&huart1) != HAL_OK)
  {
    Error_Handler();
  }

}

/**
  * Enable MDMA controller clock
  */
static void MX_MDMA_Init(void)
{

  /* MDMA controller clock enable */
  __HAL_RCC_MDMA_CLK_ENABLE();
  /* Local variables */

  /* MDMA interrupt initialization */
  /* MDMA_IRQn interrupt configuration */
  HAL_NVIC_SetPriority(MDMA_IRQn, 5, 0);
  HAL_NVIC_EnableIRQ(MDMA_IRQn);

}

/* FMC initialization function */
static void MX_FMC_Init(void)
{

  FMC_SDRAM_TimingTypeDef SdramTiming = {0};

  /** Perform the SDRAM1 memory initialization sequence
  */
  hsdram1.Instance = FMC_SDRAM_DEVICE;
  /* hsdram1.Init */
  hsdram1.Init.SDBank = FMC_SDRAM_BANK2;
  hsdram1.Init.ColumnBitsNumber = FMC_SDRAM_COLUMN_BITS_NUM_8;
  hsdram1.Init.RowBitsNumber = FMC_SDRAM_ROW_BITS_NUM_12;
  hsdram1.Init.MemoryDataWidth = FMC_SDRAM_MEM_BUS_WIDTH_16;
  hsdram1.Init.InternalBankNumber = FMC_SDRAM_INTERN_BANKS_NUM_4;
  hsdram1.Init.CASLatency = FMC_SDRAM_CAS_LATENCY_3;
  hsdram1.Init.WriteProtection = FMC_SDRAM_WRITE_PROTECTION_DISABLE;
  hsdram1.Init.SDClockPeriod = FMC_SDRAM_CLOCK_PERIOD_2;
  hsdram1.Init.ReadBurst = FMC_SDRAM_RBURST_ENABLE;
  hsdram1.Init.ReadPipeDelay = FMC_SDRAM_RPIPE_DELAY_0;
  /* SdramTiming */
  SdramTiming.LoadToActiveDelay = 2;
  SdramTiming.ExitSelfRefreshDelay = 7;
  SdramTiming.SelfRefreshTime = 4;
  SdramTiming.RowCycleDelay = 7;
  SdramTiming.WriteRecoveryTime = 5;
  SdramTiming.RPDelay = 2;
  SdramTiming.RCDDelay = 2;

  if (HAL_SDRAM_Init(&hsdram1, &SdramTiming) != HAL_OK)
  {
    Error_Handler( );
  }

  /* USER CODE BEGIN FMC_Init 2 */
  BSP_SDRAM_DeInit(0);
  if(BSP_SDRAM_Init(0) != BSP_ERROR_NONE)
  {
	  Error_Handler( );
  }
  /* USER CODE END FMC_Init 2 */
}

static void MX_GPIO_Init(void)
{
  GPIO_InitTypeDef GPIO_InitStruct = {0};

  /* GPIO Ports Clock Enable */
  __HAL_RCC_GPIOI_CLK_ENABLE();
  __HAL_RCC_GPIOB_CLK_ENABLE();
  __HAL_RCC_GPIOK_CLK_ENABLE();
  __HAL_RCC_GPIOG_CLK_ENABLE();
  __HAL_RCC_GPIOC_CLK_ENABLE();
  __HAL_RCC_GPIOA_CLK_ENABLE();
  __HAL_RCC_GPIOE_CLK_ENABLE();
  __HAL_RCC_GPIOJ_CLK_ENABLE();
  __HAL_RCC_GPIOD_CLK_ENABLE();
  __HAL_RCC_GPIOH_CLK_ENABLE();
  __HAL_RCC_GPIOF_CLK_ENABLE();

  /*Configure GPIO pin Output Level */
  HAL_GPIO_WritePin(LD2_GPIO_Port, LD2_Pin, GPIO_PIN_RESET);

  /*Configure GPIO pin Output Level */
  HAL_GPIO_WritePin(GPIOB, MII_TX_ER_nINT_Pin|LCD_RST_Pin, GPIO_PIN_RESET);

  /*Configure GPIO pin Output Level */
  HAL_GPIO_WritePin(LD1_GPIO_Port, LD1_Pin, GPIO_PIN_RESET);

  /*Configure GPIO pins : PI6 PI5 PI4 PI7 */
  GPIO_InitStruct.Pin = GPIO_PIN_6|GPIO_PIN_5|GPIO_PIN_4|GPIO_PIN_7;
  GPIO_InitStruct.Mode = GPIO_MODE_AF_PP;
  GPIO_InitStruct.Pull = GPIO_NOPULL;
  GPIO_InitStruct.Speed = GPIO_SPEED_FREQ_LOW;
  GPIO_InitStruct.Alternate = GPIO_AF10_SAI2;
  HAL_GPIO_Init(GPIOI, &GPIO_InitStruct);

  /*Configure GPIO pins : FDCAN2_RX_Pin FDCAN2_TX_Pin */
  GPIO_InitStruct.Pin = FDCAN2_RX_Pin|FDCAN2_TX_Pin;
  GPIO_InitStruct.Mode = GPIO_MODE_AF_PP;
  GPIO_InitStruct.Pull = GPIO_NOPULL;
  GPIO_InitStruct.Speed = GPIO_SPEED_FREQ_LOW;
  GPIO_InitStruct.Alternate = GPIO_AF9_FDCAN2;
  HAL_GPIO_Init(GPIOB, &GPIO_InitStruct);

  /*Configure GPIO pin : PG10 */
  GPIO_InitStruct.Pin = GPIO_PIN_10;
  GPIO_InitStruct.Mode = GPIO_MODE_AF_PP;
  GPIO_InitStruct.Pull = GPIO_NOPULL;
  GPIO_InitStruct.Speed = GPIO_SPEED_FREQ_LOW;
  GPIO_InitStruct.Alternate = GPIO_AF10_SAI2;
  HAL_GPIO_Init(GPIOG, &GPIO_InitStruct);

  /*Configure GPIO pin : PB4 */
  GPIO_InitStruct.Pin = GPIO_PIN_4;
  GPIO_InitStruct.Mode = GPIO_MODE_AF_PP;
  GPIO_InitStruct.Pull = GPIO_NOPULL;
  GPIO_InitStruct.Speed = GPIO_SPEED_FREQ_LOW;
  GPIO_InitStruct.Alternate = GPIO_AF7_SPI2;
  HAL_GPIO_Init(GPIOB, &GPIO_InitStruct);

  /*Configure GPIO pins : MII_TX_EN_Pin MII_TXD1_Pin MII_TXD0_Pin */
  GPIO_InitStruct.Pin = MII_TX_EN_Pin|MII_TXD1_Pin|MII_TXD0_Pin;
  GPIO_InitStruct.Mode = GPIO_MODE_AF_PP;
  GPIO_InitStruct.Pull = GPIO_NOPULL;
  GPIO_InitStruct.Speed = GPIO_SPEED_FREQ_LOW;
  GPIO_InitStruct.Alternate = GPIO_AF11_ETH;
  HAL_GPIO_Init(GPIOG, &GPIO_InitStruct);

  /*Configure GPIO pin : PD3 */
  GPIO_InitStruct.Pin = GPIO_PIN_3;
  GPIO_InitStruct.Mode = GPIO_MODE_AF_PP;
  GPIO_InitStruct.Pull = GPIO_NOPULL;
  GPIO_InitStruct.Speed = GPIO_SPEED_FREQ_LOW;
  GPIO_InitStruct.Alternate = GPIO_AF5_SPI2;
  HAL_GPIO_Init(GPIOD, &GPIO_InitStruct);

  /*Configure GPIO pin : PI2 */
  GPIO_InitStruct.Pin = GPIO_PIN_2;
  GPIO_InitStruct.Mode = GPIO_MODE_AF_PP;
  GPIO_InitStruct.Pull = GPIO_NOPULL;
  GPIO_InitStruct.Speed = GPIO_SPEED_FREQ_LOW;
  GPIO_InitStruct.Alternate = GPIO_AF5_SPI2;
  HAL_GPIO_Init(GPIOI, &GPIO_InitStruct);

  /*Configure GPIO pin : PH15 */
  GPIO_InitStruct.Pin = GPIO_PIN_15;
  GPIO_InitStruct.Mode = GPIO_MODE_AF_PP;
  GPIO_InitStruct.Pull = GPIO_NOPULL;
  GPIO_InitStruct.Speed = GPIO_SPEED_FREQ_LOW;
  GPIO_InitStruct.Alternate = GPIO_AF3_TIM8;
  HAL_GPIO_Init(GPIOH, &GPIO_InitStruct);

  /*Configure GPIO pins : FDCAN1_RX_Pin FDCAN1_TX_Pin */
  GPIO_InitStruct.Pin = FDCAN1_RX_Pin|FDCAN1_TX_Pin;
  GPIO_InitStruct.Mode = GPIO_MODE_AF_PP;
  GPIO_InitStruct.Pull = GPIO_NOPULL;
  GPIO_InitStruct.Speed = GPIO_SPEED_FREQ_LOW;
  GPIO_InitStruct.Alternate = GPIO_AF9_FDCAN1;
  HAL_GPIO_Init(GPIOH, &GPIO_InitStruct);

  /*Configure GPIO pin : MII_TXD3_Pin */
  GPIO_InitStruct.Pin = MII_TXD3_Pin;
  GPIO_InitStruct.Mode = GPIO_MODE_AF_PP;
  GPIO_InitStruct.Pull = GPIO_NOPULL;
  GPIO_InitStruct.Speed = GPIO_SPEED_FREQ_LOW;
  GPIO_InitStruct.Alternate = GPIO_AF11_ETH;
  HAL_GPIO_Init(MII_TXD3_GPIO_Port, &GPIO_InitStruct);

  /*Configure GPIO pin : LCD_DISPD7_Pin */
  GPIO_InitStruct.Pin = LCD_DISPD7_Pin;
  GPIO_InitStruct.Mode = GPIO_MODE_INPUT;
  GPIO_InitStruct.Pull = GPIO_NOPULL;
  HAL_GPIO_Init(LCD_DISPD7_GPIO_Port, &GPIO_InitStruct);

  /*Configure GPIO pins : PE5 PE4 */
  GPIO_InitStruct.Pin = GPIO_PIN_5|GPIO_PIN_4;
  GPIO_InitStruct.Mode = GPIO_MODE_AF_PP;
  GPIO_InitStruct.Pull = GPIO_NOPULL;
  GPIO_InitStruct.Speed = GPIO_SPEED_FREQ_LOW;
  GPIO_InitStruct.Alternate = GPIO_AF10_SAI4;
  HAL_GPIO_Init(GPIOE, &GPIO_InitStruct);

  /*Configure GPIO pins : USB_OTG_FS2_ID_Pin OTG_FS2_PSO_Pin */
  GPIO_InitStruct.Pin = USB_OTG_FS2_ID_Pin|OTG_FS2_PSO_Pin;
  GPIO_InitStruct.Mode = GPIO_MODE_INPUT;
  GPIO_InitStruct.Pull = GPIO_NOPULL;
  HAL_GPIO_Init(GPIOA, &GPIO_InitStruct);

  /*Configure GPIO pin : B1_Pin */
  GPIO_InitStruct.Pin = B1_Pin;
  GPIO_InitStruct.Mode = GPIO_MODE_INPUT;
  GPIO_InitStruct.Pull = GPIO_NOPULL;
  HAL_GPIO_Init(B1_GPIO_Port, &GPIO_InitStruct);

  /*Configure GPIO pin : PA8 */
  GPIO_InitStruct.Pin = GPIO_PIN_8;
  GPIO_InitStruct.Mode = GPIO_MODE_AF_PP;
  GPIO_InitStruct.Pull = GPIO_NOPULL;
  GPIO_InitStruct.Speed = GPIO_SPEED_FREQ_LOW;
  GPIO_InitStruct.Alternate = GPIO_AF1_TIM1;
  HAL_GPIO_Init(GPIOA, &GPIO_InitStruct);

  /*Configure GPIO pins : USB_OTG_FS2_P_Pin USB_OTG_FS2_N_Pin */
  GPIO_InitStruct.Pin = USB_OTG_FS2_P_Pin|USB_OTG_FS2_N_Pin;
  GPIO_InitStruct.Mode = GPIO_MODE_AF_PP;
  GPIO_InitStruct.Pull = GPIO_NOPULL;
  GPIO_InitStruct.Speed = GPIO_SPEED_FREQ_LOW;
  GPIO_InitStruct.Alternate = GPIO_AF10_OTG1_FS;
  HAL_GPIO_Init(GPIOA, &GPIO_InitStruct);

  /*Configure GPIO pin : MII_RX_ER_Pin */
  GPIO_InitStruct.Pin = MII_RX_ER_Pin;
  GPIO_InitStruct.Mode = GPIO_MODE_AF_PP;
  GPIO_InitStruct.Pull = GPIO_NOPULL;
  GPIO_InitStruct.Speed = GPIO_SPEED_FREQ_LOW;
  GPIO_InitStruct.Alternate = GPIO_AF11_ETH;
  HAL_GPIO_Init(MII_RX_ER_GPIO_Port, &GPIO_InitStruct);

  /*Configure GPIO pin : LD2_Pin */
  GPIO_InitStruct.Pin = LD2_Pin;
  GPIO_InitStruct.Mode = GPIO_MODE_OUTPUT_PP;
  GPIO_InitStruct.Pull = GPIO_NOPULL;
  GPIO_InitStruct.Speed = GPIO_SPEED_FREQ_LOW;
  HAL_GPIO_Init(LD2_GPIO_Port, &GPIO_InitStruct);

  /*Configure GPIO pin : LCD_INT_Pin */
  GPIO_InitStruct.Pin = LCD_INT_Pin;
  GPIO_InitStruct.Mode = GPIO_MODE_IT_RISING;
  GPIO_InitStruct.Pull = GPIO_NOPULL;
  HAL_GPIO_Init(LCD_INT_GPIO_Port, &GPIO_InitStruct);

  /*Configure GPIO pin : LCD_BL_Pin */
  GPIO_InitStruct.Pin = LCD_BL_Pin;
  GPIO_InitStruct.Mode = GPIO_MODE_INPUT;
  GPIO_InitStruct.Pull = GPIO_NOPULL;
  HAL_GPIO_Init(LCD_BL_GPIO_Port, &GPIO_InitStruct);

  /*Configure GPIO pin : PF8 */
  GPIO_InitStruct.Pin = GPIO_PIN_8;
  GPIO_InitStruct.Mode = GPIO_MODE_ANALOG;
  GPIO_InitStruct.Pull = GPIO_NOPULL;
  HAL_GPIO_Init(GPIOF, &GPIO_InitStruct);

  /*Configure GPIO pin : PC0 */
  GPIO_InitStruct.Pin = GPIO_PIN_0;
  GPIO_InitStruct.Mode = GPIO_MODE_ANALOG;
  GPIO_InitStruct.Pull = GPIO_NOPULL;
  HAL_GPIO_Init(GPIOC, &GPIO_InitStruct);

  /*Configure GPIO pins : MII_MDC_Pin MII_TXD2_Pin MII_TX_CLK_Pin MII_RXD0_Pin
                           MII_RXD1_Pin */
  GPIO_InitStruct.Pin = MII_MDC_Pin|MII_TXD2_Pin|MII_TX_CLK_Pin|MII_RXD0_Pin
                          |MII_RXD1_Pin;
  GPIO_InitStruct.Mode = GPIO_MODE_AF_PP;
  GPIO_InitStruct.Pull = GPIO_NOPULL;
  GPIO_InitStruct.Speed = GPIO_SPEED_FREQ_LOW;
  GPIO_InitStruct.Alternate = GPIO_AF11_ETH;
  HAL_GPIO_Init(GPIOC, &GPIO_InitStruct);

  /*Configure GPIO pins : MII_CRS_Pin MII_COL_Pin */
  GPIO_InitStruct.Pin = MII_CRS_Pin|MII_COL_Pin;
  GPIO_InitStruct.Mode = GPIO_MODE_AF_PP;
  GPIO_InitStruct.Pull = GPIO_NOPULL;
  GPIO_InitStruct.Speed = GPIO_SPEED_FREQ_LOW;
  GPIO_InitStruct.Alternate = GPIO_AF11_ETH;
  HAL_GPIO_Init(GPIOH, &GPIO_InitStruct);

  /*Configure GPIO pins : MII_MDIO_Pin MII_RX_CLK_Pin MII_RX_DV_Pin */
  GPIO_InitStruct.Pin = MII_MDIO_Pin|MII_RX_CLK_Pin|MII_RX_DV_Pin;
  GPIO_InitStruct.Mode = GPIO_MODE_AF_PP;
  GPIO_InitStruct.Pull = GPIO_NOPULL;
  GPIO_InitStruct.Speed = GPIO_SPEED_FREQ_LOW;
  GPIO_InitStruct.Alternate = GPIO_AF11_ETH;
  HAL_GPIO_Init(GPIOA, &GPIO_InitStruct);

  /*Configure GPIO pins : VCP_TX_Pin VCP_RX_Pin */
  GPIO_InitStruct.Pin = VCP_TX_Pin|VCP_RX_Pin;
  GPIO_InitStruct.Mode = GPIO_MODE_AF_PP;
  GPIO_InitStruct.Pull = GPIO_NOPULL;
  GPIO_InitStruct.Speed = GPIO_SPEED_FREQ_LOW;
  GPIO_InitStruct.Alternate = GPIO_AF7_USART3;
  HAL_GPIO_Init(GPIOB, &GPIO_InitStruct);

  /*Configure GPIO pin : OTG_FS2_OverCurrent_Pin */
  GPIO_InitStruct.Pin = OTG_FS2_OverCurrent_Pin;
  GPIO_InitStruct.Mode = GPIO_MODE_IT_RISING;
  GPIO_InitStruct.Pull = GPIO_NOPULL;
  HAL_GPIO_Init(OTG_FS2_OverCurrent_GPIO_Port, &GPIO_InitStruct);

  /*Configure GPIO pin : PA6 */
  GPIO_InitStruct.Pin = GPIO_PIN_6;
  GPIO_InitStruct.Mode = GPIO_MODE_AF_PP;
  GPIO_InitStruct.Pull = GPIO_NOPULL;
  GPIO_InitStruct.Speed = GPIO_SPEED_FREQ_LOW;
  GPIO_InitStruct.Alternate = GPIO_AF9_TIM13;
  HAL_GPIO_Init(GPIOA, &GPIO_InitStruct);

  /*Configure GPIO pins : MII_TX_ER_nINT_Pin LCD_RST_Pin */
  GPIO_InitStruct.Pin = MII_TX_ER_nINT_Pin|LCD_RST_Pin;
  GPIO_InitStruct.Mode = GPIO_MODE_OUTPUT_PP;
  GPIO_InitStruct.Pull = GPIO_NOPULL;
  GPIO_InitStruct.Speed = GPIO_SPEED_FREQ_LOW;
  HAL_GPIO_Init(GPIOB, &GPIO_InitStruct);

  /*Configure GPIO pins : MII_RX_D3_Pin MII_RX_D2_Pin */
  GPIO_InitStruct.Pin = MII_RX_D3_Pin|MII_RX_D2_Pin;
  GPIO_InitStruct.Mode = GPIO_MODE_AF_PP;
  GPIO_InitStruct.Pull = GPIO_NOPULL;
  GPIO_InitStruct.Speed = GPIO_SPEED_FREQ_LOW;
  GPIO_InitStruct.Alternate = GPIO_AF11_ETH;
  HAL_GPIO_Init(GPIOB, &GPIO_InitStruct);

  /*Configure GPIO pin : LD1_Pin */
  GPIO_InitStruct.Pin = LD1_Pin;
  GPIO_InitStruct.Mode = GPIO_MODE_OUTPUT_PP;
  GPIO_InitStruct.Pull = GPIO_NOPULL;
  GPIO_InitStruct.Speed = GPIO_SPEED_FREQ_LOW;
  HAL_GPIO_Init(LD1_GPIO_Port, &GPIO_InitStruct);

  /*Configure GPIO pin : PB15 */
  GPIO_InitStruct.Pin = GPIO_PIN_15;
  GPIO_InitStruct.Mode = GPIO_MODE_AF_PP;
  GPIO_InitStruct.Pull = GPIO_NOPULL;
  GPIO_InitStruct.Speed = GPIO_SPEED_FREQ_LOW;
  GPIO_InitStruct.Alternate = GPIO_AF5_SPI2;
  HAL_GPIO_Init(GPIOB, &GPIO_InitStruct);

  /*AnalogSwitch Config */
  HAL_SYSCFG_AnalogSwitchConfig(SYSCFG_SWITCH_PC2, SYSCFG_SWITCH_PC2_OPEN);

  /*AnalogSwitch Config */
  HAL_SYSCFG_AnalogSwitchConfig(SYSCFG_SWITCH_PC3, SYSCFG_SWITCH_PC3_OPEN);

  /*AnalogSwitch Config */
  HAL_SYSCFG_AnalogSwitchConfig(SYSCFG_SWITCH_PA0, SYSCFG_SWITCH_PA0_OPEN);

  /*AnalogSwitch Config */
  HAL_SYSCFG_AnalogSwitchConfig(SYSCFG_SWITCH_PA1, SYSCFG_SWITCH_PA1_OPEN);

}

void StartDefaultTask(void *argument)
{
  for(;;)
  {
    osDelay(1);
  }
}

void micListenTask_handler(void *argument)
{
  /* USER CODE BEGIN micListenTask_handler */
  /* Infinite loop */
  for(;;)
  {
    const int8_t *buffer = pv_audio_rec_get_new_buffer();
    if (buffer) {

	  const pv_status_t status = pv_picovoice_process(pvhandle, buffer);
	  if (status != PV_STATUS_SUCCESS) {

	    printf("Picovoice process failed with '%s'", pv_status_to_string(status));
	    Error_Handler();
	  }
    }
    osDelay(1);
  }
  /* USER CODE END micListenTask_handler */
}

void consumerTask_handler(void *argument)
{
  /* USER CODE BEGIN consumerTask_handler */

  ControlType* controlType = NULL;
  /* Infinite loop */
  for(;;)
  {
	if(xQueueReceive(controlQueueHandle, (void*) controlType, 0) == pdFALSE) {
	  osDelay(200);
	}
  }
  /* USER CODE END consumerTask_handler */
}

void providerTask_handler(void *argument)
{
  /* USER CODE BEGIN providerTask_handler */
  /* Infinite loop */
  if(argument == NULL) {
	vTaskDelete(NULL);
  }

  xQueueSendToBack(controlQueueHandle, (ControlType*) argument, 0);
  vTaskDelete(NULL);
  /* USER CODE END providerTask_handler */
}

void HAL_TIM_PeriodElapsedCallback(TIM_HandleTypeDef *htim)
{
  if (htim->Instance == TIM6) {
    HAL_IncTick();
  }
}

void Error_Handler(void)
{
  __disable_irq();
  while (1)
  {
  }
}
